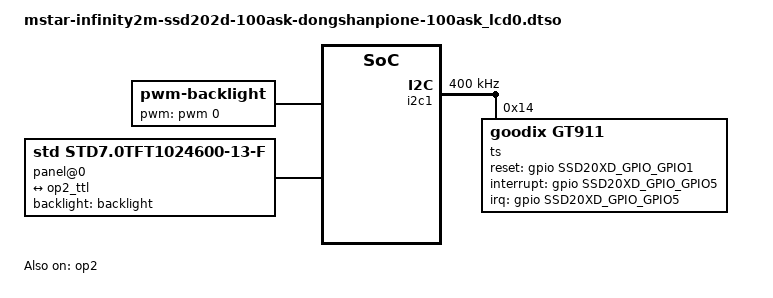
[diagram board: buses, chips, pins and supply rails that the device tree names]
// SPDX-License-Identifier: GPL-2.0-or-later
/*
 * Copyright (c) 2022 thingy.jp.
 * Author: Daniel Palmer <daniel@thingy.jp>
 */

/dts-v1/;
/plugin/;

#include <dt-bindings/clock/mstar-msc313-clkgen.h>
#include <dt-bindings/clock/mstar-msc313-sc-gp.h>
#include <dt-bindings/gpio/gpio.h>
#include <dt-bindings/gpio/msc313-gpio.h>
#include <dt-bindings/interrupt-controller/irq.h>

&{/} {
	backlight: backlight {
		compatible = "pwm-backlight";
		pwms = <&pwm 0 50000>;
		brightness-levels = <0 4 8 16 32 64 128 255>;
		default-brightness-level = <6>;
		pinctrl-names = "default";
		pinctrl-0 = <&pwm0_mode3_pins>;
	};

	panel@0 {
		compatible = "std,std7.0tft1024600-13-f";
		reg = <0>;
		pinctrl-names = "default";
		pinctrl-0 = <&ttl_mode1_pins>;
		backlight = <&backlight>;
		rotation = <180>;
		port {
			panel_in: endpoint {
				remote-endpoint = <&op2_ttl>;
			};
		};
	};
};

&display {
	ports = <&mopg>,<&mops>,<&gop0>,<&gop1>,<&op2>,<&displaytop>;
};

&op2 {
	mstar,op2-channelswap = /bits/ 8 <0x1 0x2 0x3>;
	assigned-clocks = <&clkgen MSC313_CLKGEN_MUXES SSD20XD_CLKGEN_SC_PIXEL 0>,
			  <&sc_gp_ctrl_muxes SSD20XD_SC_GP_HDMI_GATE_MUX>;
	assigned-clock-parents = <&clkgen MSC313_CLKGEN_DIVIDERS MSC313_CLKGEN_GATE_9 GATE9_DIVIDEBY_4>,
				 <&clkgen MSC313_CLKGEN_DEGLITCHES SSD20XD_CLKGEN_SC_PIXEL 0>;
	status = "okay";
};

&op2_ttl {
	remote-endpoint = <&panel_in>;
};

&i2c1 {
	pinctrl-names = "default";
	pinctrl-0 = <&i2c1_mode1_pins>;
	clock-frequency = <400000>;
	status = "okay";

	ts@5d {
		compatible = "goodix,gt911";
		reg = <0x14>;
		interrupts-extended = <&gpio SSD20XD_GPIO_GPIO5 IRQ_TYPE_EDGE_FALLING>;
		reset-gpios = <&gpio SSD20XD_GPIO_GPIO1 GPIO_ACTIVE_HIGH>;
		interrupt-gpios = <&gpio SSD20XD_GPIO_GPIO5 GPIO_ACTIVE_HIGH>;
	};
};
